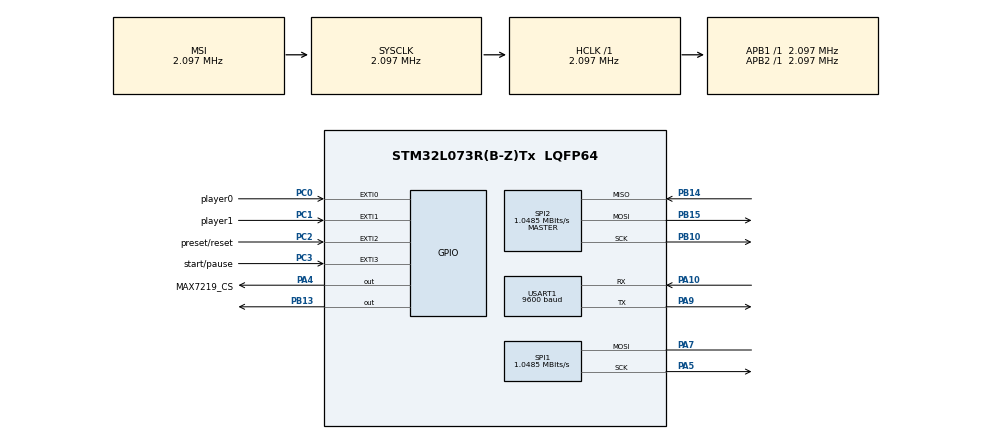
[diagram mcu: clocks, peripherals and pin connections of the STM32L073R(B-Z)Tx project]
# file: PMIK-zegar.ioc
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FATFS._MAX_SS=4096
FATFS._USE_LFN=1
Mcu.Family=STM32L0
Mcu.Name=STM32L073R(B-Z)Tx
Mcu.Package=LQFP64
NVIC.EXTI0_1_IRQn=true\:0\:0\:false\:false\:true\:true\:true\:true
NVIC.EXTI2_3_IRQn=true\:0\:0\:false\:false\:true\:true\:true\:true
NVIC.TIM2_IRQn=true\:0\:0\:false\:false\:true\:true\:true\:true
NVIC.TIM3_IRQn=true\:0\:0\:false\:false\:true\:true\:true\:true
PA10.Mode=Asynchronous
PA10.Signal=USART1_RX
PA13.GPIO_Label=TMS
PA13.Mode=Serial_Wire
PA13.Signal=SYS_SWDIO
PA14.GPIO_Label=TCK
PA14.Mode=Serial_Wire
PA14.Signal=SYS_SWCLK
PA3.GPIO_Label=USART_RX
PA3.Signal=USART2_RX
PA4.GPIO_Label=MAX7219_CS
PA4.Signal=GPIO_Output
PA5.Mode=Simplex_Bidirectional_Master
PA5.Signal=SPI1_SCK
PA7.Mode=Simplex_Bidirectional_Master
PA7.Signal=SPI1_MOSI
PA9.Mode=Asynchronous
PA9.Signal=USART1_TX
PB10.Mode=Full_Duplex_Master
PB10.Signal=SPI2_SCK
PB13.Signal=GPIO_Output
PB14.Mode=Full_Duplex_Master
PB14.Signal=SPI2_MISO
PB15.Mode=Full_Duplex_Master
PB15.Signal=SPI2_MOSI
PC0.GPIO_Label=player0
PC0.Signal=GPXTI0
PC1.GPIO_Label=player1
PC1.Signal=GPXTI1
PC14-OSC32_IN.Signal=RCC_OSC32_IN
PC15-OSC32_OUT.Signal=RCC_OSC32_OUT
PC2.GPIO_Label=preset/reset
PC2.Signal=GPXTI2
PC3.GPIO_Label=start/pause
PC3.Signal=GPXTI3
PH0-OSC_IN.GPIO_Label=MCO
PH0-OSC_IN.Signal=RCC_OSC_IN
ProjectManager.HeapSize=0x200
ProjectManager.StackSize=0x400
ProjectManager.TargetToolchain=STM32CubeIDE
RCC.AHBFreq_Value=2097000
RCC.APB1Freq_Value=2097000
RCC.APB1TimFreq_Value=2097000
RCC.APB2Freq_Value=2097000
RCC.APB2TimFreq_Value=2097000
RCC.HSE_VALUE=8000000
RCC.HSI16_VALUE=16000000
RCC.HSI48_VALUE=48000000
RCC.HSI_VALUE=16000000
RCC.LSEState=RCC_LSE_ON
RCC.LSE_VALUE=32768
RCC.MSI_VALUE=2097000
RCC.SYSCLKFreq_VALUE=2097000
RCC.VCOOutputFreq_Value=48000000
SPI1.CalculateBaudRate=1.0485 MBits/s
SPI1.Direction=SPI_DIRECTION_1LINE
SPI1.Mode=SPI_MODE_MASTER
SPI1.VirtualType=VM_MASTER
SPI2.CalculateBaudRate=1.0485 MBits/s
SPI2.Direction=SPI_DIRECTION_2LINES
SPI2.Mode=SPI_MODE_MASTER
SPI2.VirtualType=VM_MASTER
TIM2.AutoReloadPreload=TIM_AUTORELOAD_PRELOAD_ENABLE
TIM2.Period=1000
TIM2.Prescaler=2080
TIM3.AutoReloadPreload=TIM_AUTORELOAD_PRELOAD_ENABLE
TIM3.Period=250
TIM3.Prescaler=2080
USART1.BaudRate=9600
USART1.VirtualMode-Asynchronous=VM_ASYNC
VP_FATFS_VS_Generic.Mode=User_defined
VP_TIM2_VS_ClockSourceINT.Mode=Internal
VP_TIM3_VS_ClockSourceINT.Mode=Internal
board=NUCLEO-L073RZ

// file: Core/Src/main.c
/* USER CODE BEGIN Header */
/**
  ******************************************************************************
  * @file           : main.c
  * @brief          : Chess clock
  * @authors		: Szymon Klimaszewski, KajetanLachanski
  * @description	:
  *
  * Chess clock using MAX7219 8*7-segment display,
  * switch-buttons, SD card for game data storage
  * and ESP32 for wifi data transfer.
  *
  ******************************************************************************
  */
/* USER CODE END Header */
#include "main.h"
#include "fatfs.h"

/* USER CODE BEGIN Includes */
#include "max7219_digits.h"
/* USER CODE END Includes */

/* USER CODE BEGIN PD */
FATFS fs;
FIL fil;
char buffer[100];
//char message[] = "hi stm\n";	//CHANGE
/* USER CODE END PD */

SPI_HandleTypeDef hspi1;
SPI_HandleTypeDef hspi2;

TIM_HandleTypeDef htim2;
TIM_HandleTypeDef htim3;

UART_HandleTypeDef huart1;

/* USER CODE BEGIN PV */
extern char printString[20];
/* USER CODE END PV */

void SystemClock_Config(void);
static void MX_GPIO_Init(void);
static void MX_TIM3_Init(void);
static void MX_SPI1_Init(void);
static void MX_SPI2_Init(void);
static void MX_USART1_UART_Init(void);
static void MX_TIM2_Init(void);

int main(void)
{

  /* MCU Configuration--------------------------------------------------------*/

  /* Reset of all peripherals, Initializes the Flash interface and the Systick. */
  HAL_Init();

  /* Configure the system clock */
  SystemClock_Config();

  /* Initialize all configured peripherals */
  MX_GPIO_Init();
  MX_TIM3_Init();
  MX_SPI1_Init();
  MX_SPI2_Init();
  MX_FATFS_Init();
  MX_USART1_UART_Init();
  MX_TIM2_Init();
  /* USER CODE BEGIN 2 */
  initialise_monitor_handles();	//semihosting
  HAL_TIM_Base_Start_IT(&htim3);

  MAX7219_Init(&hspi1);
  MAX7219_PutString(0, printString);	// initial display

  /**************************************
   Example SD-Card saving (init-only)

  HAL_Delay(500);
  f_mount(&fs, "", 0);
  f_open(&fil, "write.txt", FA_OPEN_ALWAYS | FA_WRITE | FA_READ);
  f_lseek(&fil,f_size(&fil)); //change
  f_puts("Chess clock init\n", &fil);
  f_close(&fil);

  **************************************/

  /* USER CODE END 2 */

  /* Infinite loop */
  /* USER CODE BEGIN WHILE */
  while (1)
  {
	  // program logic in interrupts
    /* USER CODE END WHILE */

    /* USER CODE BEGIN 3 */
//	HAL_UART_Transmit(&huart1, (uint8_t*) message, strlen(message), HAL_MAX_DELAY);
  }
  /* USER CODE END 3 */
}

void SystemClock_Config(void)
{
  RCC_OscInitTypeDef RCC_OscInitStruct = {0};
  RCC_ClkInitTypeDef RCC_ClkInitStruct = {0};
  RCC_PeriphCLKInitTypeDef PeriphClkInit = {0};

  /** Configure the main internal regulator output voltage
  */
  __HAL_PWR_VOLTAGESCALING_CONFIG(PWR_REGULATOR_VOLTAGE_SCALE1);

  /** Initializes the RCC Oscillators according to the specified parameters
  * in the RCC_OscInitTypeDef structure.
  */
  RCC_OscInitStruct.OscillatorType = RCC_OSCILLATORTYPE_MSI;
  RCC_OscInitStruct.MSIState = RCC_MSI_ON;
  RCC_OscInitStruct.MSICalibrationValue = 0;
  RCC_OscInitStruct.MSIClockRange = RCC_MSIRANGE_5;
  RCC_OscInitStruct.PLL.PLLState = RCC_PLL_NONE;
  if (HAL_RCC_OscConfig(&RCC_OscInitStruct) != HAL_OK)
  {
    Error_Handler();
  }

  /** Initializes the CPU, AHB and APB buses clocks
  */
  RCC_ClkInitStruct.ClockType = RCC_CLOCKTYPE_HCLK|RCC_CLOCKTYPE_SYSCLK
                              |RCC_CLOCKTYPE_PCLK1|RCC_CLOCKTYPE_PCLK2;
  RCC_ClkInitStruct.SYSCLKSource = RCC_SYSCLKSOURCE_MSI;
  RCC_ClkInitStruct.AHBCLKDivider = RCC_SYSCLK_DIV1;
  RCC_ClkInitStruct.APB1CLKDivider = RCC_HCLK_DIV1;
  RCC_ClkInitStruct.APB2CLKDivider = RCC_HCLK_DIV1;

  if (HAL_RCC_ClockConfig(&RCC_ClkInitStruct, FLASH_LATENCY_0) != HAL_OK)
  {
    Error_Handler();
  }
  PeriphClkInit.PeriphClockSelection = RCC_PERIPHCLK_USART1;
  PeriphClkInit.Usart1ClockSelection = RCC_USART1CLKSOURCE_PCLK2;
  if (HAL_RCCEx_PeriphCLKConfig(&PeriphClkInit) != HAL_OK)
  {
    Error_Handler();
  }
}

static void MX_SPI1_Init(void)
{

  /* SPI1 parameter configuration*/
  hspi1.Instance = SPI1;
  hspi1.Init.Mode = SPI_MODE_MASTER;
  hspi1.Init.Direction = SPI_DIRECTION_1LINE;
  hspi1.Init.DataSize = SPI_DATASIZE_8BIT;
  hspi1.Init.CLKPolarity = SPI_POLARITY_LOW;
  hspi1.Init.CLKPhase = SPI_PHASE_1EDGE;
  hspi1.Init.NSS = SPI_NSS_SOFT;
  hspi1.Init.BaudRatePrescaler = SPI_BAUDRATEPRESCALER_2;
  hspi1.Init.FirstBit = SPI_FIRSTBIT_MSB;
  hspi1.Init.TIMode = SPI_TIMODE_DISABLE;
  hspi1.Init.CRCCalculation = SPI_CRCCALCULATION_DISABLE;
  hspi1.Init.CRCPolynomial = 7;
  if (HAL_SPI_Init(&hspi1) != HAL_OK)
  {
    Error_Handler();
  }

}

static void MX_SPI2_Init(void)
{

  /* SPI2 parameter configuration*/
  hspi2.Instance = SPI2;
  hspi2.Init.Mode = SPI_MODE_MASTER;
  hspi2.Init.Direction = SPI_DIRECTION_2LINES;
  hspi2.Init.DataSize = SPI_DATASIZE_8BIT;
  hspi2.Init.CLKPolarity = SPI_POLARITY_LOW;
  hspi2.Init.CLKPhase = SPI_PHASE_1EDGE;
  hspi2.Init.NSS = SPI_NSS_SOFT;
  hspi2.Init.BaudRatePrescaler = SPI_BAUDRATEPRESCALER_2;
  hspi2.Init.FirstBit = SPI_FIRSTBIT_MSB;
  hspi2.Init.TIMode = SPI_TIMODE_DISABLE;
  hspi2.Init.CRCCalculation = SPI_CRCCALCULATION_DISABLE;
  hspi2.Init.CRCPolynomial = 7;
  if (HAL_SPI_Init(&hspi2) != HAL_OK)
  {
    Error_Handler();
  }

}

static void MX_TIM2_Init(void)
{

  TIM_ClockConfigTypeDef sClockSourceConfig = {0};
  TIM_MasterConfigTypeDef sMasterConfig = {0};

  htim2.Instance = TIM2;
  htim2.Init.Prescaler = 2080;
  htim2.Init.CounterMode = TIM_COUNTERMODE_UP;
  htim2.Init.Period = 1000;
  htim2.Init.ClockDivision = TIM_CLOCKDIVISION_DIV1;
  htim2.Init.AutoReloadPreload = TIM_AUTORELOAD_PRELOAD_ENABLE;
  if (HAL_TIM_Base_Init(&htim2) != HAL_OK)
  {
    Error_Handler();
  }
  sClockSourceConfig.ClockSource = TIM_CLOCKSOURCE_INTERNAL;
  if (HAL_TIM_ConfigClockSource(&htim2, &sClockSourceConfig) != HAL_OK)
  {
    Error_Handler();
  }
  sMasterConfig.MasterOutputTrigger = TIM_TRGO_RESET;
  sMasterConfig.MasterSlaveMode = TIM_MASTERSLAVEMODE_DISABLE;
  if (HAL_TIMEx_MasterConfigSynchronization(&htim2, &sMasterConfig) != HAL_OK)
  {
    Error_Handler();
  }

}

static void MX_TIM3_Init(void)
{

  TIM_ClockConfigTypeDef sClockSourceConfig = {0};
  TIM_MasterConfigTypeDef sMasterConfig = {0};

  htim3.Instance = TIM3;
  htim3.Init.Prescaler = 2080;
  htim3.Init.CounterMode = TIM_COUNTERMODE_UP;
  htim3.Init.Period = 250;
  htim3.Init.ClockDivision = TIM_CLOCKDIVISION_DIV1;
  htim3.Init.AutoReloadPreload = TIM_AUTORELOAD_PRELOAD_ENABLE;
  if (HAL_TIM_Base_Init(&htim3) != HAL_OK)
  {
    Error_Handler();
  }
  sClockSourceConfig.ClockSource = TIM_CLOCKSOURCE_INTERNAL;
  if (HAL_TIM_ConfigClockSource(&htim3, &sClockSourceConfig) != HAL_OK)
  {
    Error_Handler();
  }
  sMasterConfig.MasterOutputTrigger = TIM_TRGO_RESET;
  sMasterConfig.MasterSlaveMode = TIM_MASTERSLAVEMODE_DISABLE;
  if (HAL_TIMEx_MasterConfigSynchronization(&htim3, &sMasterConfig) != HAL_OK)
  {
    Error_Handler();
  }

}

static void MX_USART1_UART_Init(void)
{

  huart1.Instance = USART1;
  huart1.Init.BaudRate = 9600;
  huart1.Init.WordLength = UART_WORDLENGTH_8B;
  huart1.Init.StopBits = UART_STOPBITS_1;
  huart1.Init.Parity = UART_PARITY_NONE;
  huart1.Init.Mode = UART_MODE_TX_RX;
  huart1.Init.HwFlowCtl = UART_HWCONTROL_NONE;
  huart1.Init.OverSampling = UART_OVERSAMPLING_16;
  huart1.Init.OneBitSampling = UART_ONE_BIT_SAMPLE_DISABLE;
  huart1.AdvancedInit.AdvFeatureInit = UART_ADVFEATURE_NO_INIT;
  if (HAL_UART_Init(&huart1) != HAL_OK)
  {
    Error_Handler();
  }

}

static void MX_GPIO_Init(void)
{
  GPIO_InitTypeDef GPIO_InitStruct = {0};

  /* GPIO Ports Clock Enable */
  __HAL_RCC_GPIOC_CLK_ENABLE();
  __HAL_RCC_GPIOH_CLK_ENABLE();
  __HAL_RCC_GPIOA_CLK_ENABLE();
  __HAL_RCC_GPIOB_CLK_ENABLE();

  /*Configure GPIO pin Output Level */
  HAL_GPIO_WritePin(MAX7219_CS_GPIO_Port, MAX7219_CS_Pin, GPIO_PIN_RESET);

  /*Configure GPIO pin Output Level */
  HAL_GPIO_WritePin(GPIOB, GPIO_PIN_13, GPIO_PIN_RESET);

  /*Configure GPIO pins : player0_Pin player1_Pin preset_reset_Pin start_pause_Pin */
  GPIO_InitStruct.Pin = player0_Pin|player1_Pin|preset_reset_Pin|start_pause_Pin;
  GPIO_InitStruct.Mode = GPIO_MODE_IT_RISING;
  GPIO_InitStruct.Pull = GPIO_NOPULL;
  HAL_GPIO_Init(GPIOC, &GPIO_InitStruct);

  /*Configure GPIO pin : USART_RX_Pin */
  GPIO_InitStruct.Pin = USART_RX_Pin;
  GPIO_InitStruct.Mode = GPIO_MODE_AF_PP;
  GPIO_InitStruct.Pull = GPIO_NOPULL;
  GPIO_InitStruct.Speed = GPIO_SPEED_FREQ_VERY_HIGH;
  GPIO_InitStruct.Alternate = GPIO_AF4_USART2;
  HAL_GPIO_Init(USART_RX_GPIO_Port, &GPIO_InitStruct);

  /*Configure GPIO pin : MAX7219_CS_Pin */
  GPIO_InitStruct.Pin = MAX7219_CS_Pin;
  GPIO_InitStruct.Mode = GPIO_MODE_OUTPUT_PP;
  GPIO_InitStruct.Pull = GPIO_NOPULL;
  GPIO_InitStruct.Speed = GPIO_SPEED_FREQ_LOW;
  HAL_GPIO_Init(MAX7219_CS_GPIO_Port, &GPIO_InitStruct);

  /*Configure GPIO pin : PB13 */
  GPIO_InitStruct.Pin = GPIO_PIN_13;
  GPIO_InitStruct.Mode = GPIO_MODE_OUTPUT_PP;
  GPIO_InitStruct.Pull = GPIO_NOPULL;
  GPIO_InitStruct.Speed = GPIO_SPEED_FREQ_LOW;
  HAL_GPIO_Init(GPIOB, &GPIO_InitStruct);

  /* EXTI interrupt init*/
  HAL_NVIC_SetPriority(EXTI0_1_IRQn, 0, 0);
  HAL_NVIC_EnableIRQ(EXTI0_1_IRQn);

  HAL_NVIC_SetPriority(EXTI2_3_IRQn, 0, 0);
  HAL_NVIC_EnableIRQ(EXTI2_3_IRQn);

}

void Error_Handler(void)
{
  __disable_irq();
  while (1)
  {
  }
}
